# ATmega2560 register map
Vendor: Atmel; File version: 1.0
CPU: other r0p0, little endian, no MPU, no FPU, 4 interrupt priority bits
Registers are 8-bit, read-write, reset 0x0 unless marked. A register's access mark holds for its fields unless they carry their own. Offsets are from the block's base; [hi:lo] are bit positions; {n}, {i} and the like mark numbered series.

## USART2 — USART
Base 0x000000D0
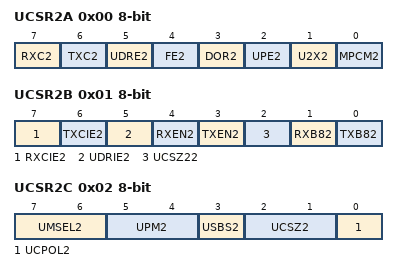
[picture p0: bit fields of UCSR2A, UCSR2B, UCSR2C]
0x00 UCSR2A — USART Control and Status Register A
  [7] RXC2 ro — USART Receive Complete
  [6] TXC2 — USART Transmit Complete
  [5] UDRE2 ro — USART Data Register Empty
  [4] FE2 ro — Framing Error
  [3] DOR2 ro — Data overRun
  [2] UPE2 ro — Parity Error
  [1] U2X2 — Double the USART transmission speed
  [0] MPCM2 — Multi-processor Communication Mode
0x01 UCSR2B — USART Control and Status Register B
  [7] RXCIE2 — RX Complete Interrupt Enable
  [6] TXCIE2 — TX Complete Interrupt Enable
  [5] UDRIE2 — USART Data register Empty Interrupt Enable
  [4] RXEN2 — Receiver Enable
  [3] TXEN2 — Transmitter Enable
  [2] UCSZ22 — Character Size
  [1] RXB82 ro — Receive Data Bit 8
  [0] TXB82 — Transmit Data Bit 8
0x02 UCSR2C — USART Control and Status Register C
  [7:6] UMSEL2 — USART Mode Select
    0=USART_ASYNC (Asynchronous USART); 1=USART_SYNC (Synchronous USART); 3=SPI_MASTER (Master SPI (MSPIM))
  [5:4] UPM2 — Parity Mode Bits
    0=DISABLED; 2=PARITY_EVEN (Enabled, Even Parity); 3=PARITY_ODD (Enabled, Odd Parity)
  [3] USBS2 — Stop Bit Select
    0=STOP1 (1-bit); 1=STOP2 (2-bit)
  [2:1] UCSZ2 — Character Size
    {v}=CHR{v+5} (Character Size: {v+5} bit) (v=0..3)
  [0] UCPOL2 — Clock Polarity
    0=RISING_EDGE (Transmit on Rising XCKn Edge, Receive on Falling XCKn Edge); 1=FALLING_EDGE (Transmit on Falling XCKn Edge, Receive on Rising XCKn Edge)
0x04 UBRR2 16-bit (reset mask 0xFF) — USART Baud Rate Register Bytes
0x06 UDR2 — USART I/O Data Register

## USART3 — USART
Base 0x00000130
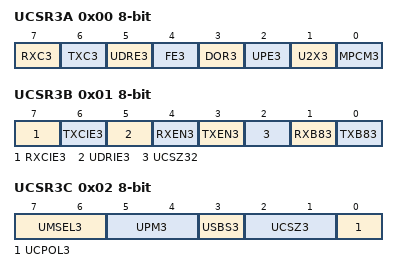
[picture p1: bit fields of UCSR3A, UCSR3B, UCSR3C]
0x00 UCSR3A — USART Control and Status Register A
  [7] RXC3 ro — USART Receive Complete
  [6] TXC3 — USART Transmit Complete
  [5] UDRE3 ro — USART Data Register Empty
  [4] FE3 ro — Framing Error
  [3] DOR3 ro — Data overRun
  [2] UPE3 ro — Parity Error
  [1] U2X3 — Double the USART transmission speed
  [0] MPCM3 — Multi-processor Communication Mode
0x01 UCSR3B — USART Control and Status Register B
  [7] RXCIE3 — RX Complete Interrupt Enable
  [6] TXCIE3 — TX Complete Interrupt Enable
  [5] UDRIE3 — USART Data register Empty Interrupt Enable
  [4] RXEN3 — Receiver Enable
  [3] TXEN3 — Transmitter Enable
  [2] UCSZ32 — Character Size
  [1] RXB83 ro — Receive Data Bit 8
  [0] TXB83 — Transmit Data Bit 8
0x02 UCSR3C — USART Control and Status Register C
  [7:6] UMSEL3 — USART Mode Select
    0=USART_ASYNC (Asynchronous USART); 1=USART_SYNC (Synchronous USART); 3=SPI_MASTER (Master SPI (MSPIM))
  [5:4] UPM3 — Parity Mode Bits
    0=DISABLED; 2=PARITY_EVEN (Enabled, Even Parity); 3=PARITY_ODD (Enabled, Odd Parity)
  [3] USBS3 — Stop Bit Select
    0=STOP1 (1-bit); 1=STOP2 (2-bit)
  [2:1] UCSZ3 — Character Size
    {v}=CHR{v+5} (Character Size: {v+5} bit) (v=0..3)
  [0] UCPOL3 — Clock Polarity
    0=RISING_EDGE (Transmit on Rising XCKn Edge, Receive on Falling XCKn Edge); 1=FALLING_EDGE (Transmit on Falling XCKn Edge, Receive on Rising XCKn Edge)
0x04 UBRR3 16-bit (reset mask 0xFF) — USART Baud Rate Register Bytes
0x06 UDR3 — USART I/O Data Register

## WDT — Watchdog Timer
Base 0x00000060
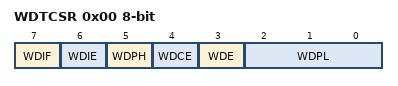
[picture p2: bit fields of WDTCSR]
0x00 WDTCSR — Watchdog Timer Control Register
  [7] WDIF — Watchdog Timeout Interrupt Flag
  [6] WDIE — Watchdog Timeout Interrupt Enable
  [5] WDPH — Watchdog Timer Prescaler - High Bit
  [4] WDCE — Watchdog Change Enable
  [3] WDE — Watch Dog Enable
  [2:0] WDPL — Watchdog Timer Prescaler - Low Bits
    0=CYCLES_2K_512K (- 2048 cycles, ~16ms/512K (524288) cycles, ~4s if WDPH is set); 1=CYCLES_4K_1024K (- 4096 cycles, ~32ms/1024K (1048576) cycles, ~8s if WDPH is set); 2=CYCLES_8K (- 8192 cycles, ~64ms); 3=CYCLES_16K (- 16K (16384) cycles, ~0.125s); 4=CYCLES_32K (- 32K (32768) cycles, ~0.25s); 5=CYCLES_64K (- 64K (65536) cycles, ~0.5s); 6=CYCLES_128K (- 128K (131072) cycles, ~1s); 7=CYCLES_256K (- 256K (262144) cycles, ~2s)
